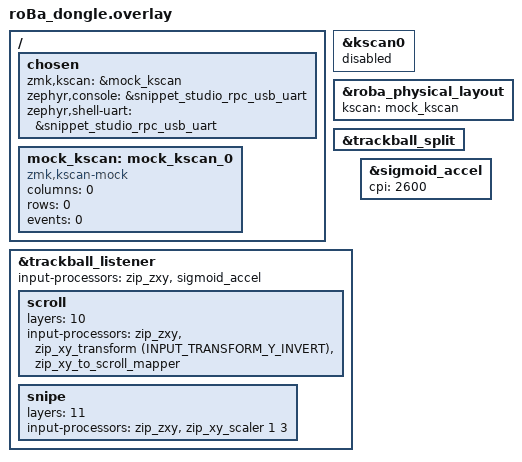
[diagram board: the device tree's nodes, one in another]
#include "roBa.dtsi"
#include <input/processors/xyz.dtsi>
#include <behaviors/input_processor_sigmoid_accel.dtsi>

/ {
    chosen {
        zmk,kscan = &mock_kscan;
        zephyr,console = &snippet_studio_rpc_usb_uart;
        zephyr,shell-uart = &snippet_studio_rpc_usb_uart;
    };

    mock_kscan: mock_kscan_0 {
        compatible = "zmk,kscan-mock";
        columns = <0>;
        rows = <0>;
        events = <0>;
    };
};

&kscan0 {
    status = "disabled";
};

&roba_physical_layout {
    kscan = <&mock_kscan>;
};

&trackball_split {
    status = "okay";
};

&trackball_listener {
    status = "okay";
    input-processors = <&zip_zxy>, <&sigmoid_accel>;

    scroll {
        layers = <10>;
        input-processors = <&zip_zxy>, <&zip_xy_transform (INPUT_TRANSFORM_Y_INVERT)>, <&zip_xy_to_scroll_mapper>;
    };

    snipe {
        layers = <11>;
        input-processors = <&zip_zxy>, <&zip_xy_scaler 1 3>;
    };
};
&sigmoid_accel {
    cpi = <2600>;
};
